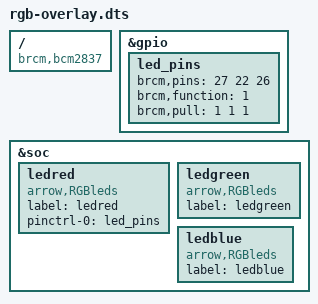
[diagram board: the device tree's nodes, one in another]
/dts-v1/;
/plugin/;

/ {
	  compatible = "brcm,bcm2837";

    fragment@0 {
        target = <&gpio>;
        __overlay__ {
            led_pins: led_pins {
              brcm,pins = <27 22 26>;
              brcm,function = <1>;
              brcm,pull = <1 1 1>;
            };
        };
    };

    fragment@1 {
        target = <&soc>;
        __overlay__ {
            ledred {
              compatible = "arrow,RGBleds";
              label = "ledred";
              pinctrl-0 = <&led_pins>;
            };

            ledgreen {
              compatible = "arrow,RGBleds";
              label = "ledgreen";
            };

            ledblue {
              compatible = "arrow,RGBleds";
              label = "ledblue";
            };
        };
    };
};
